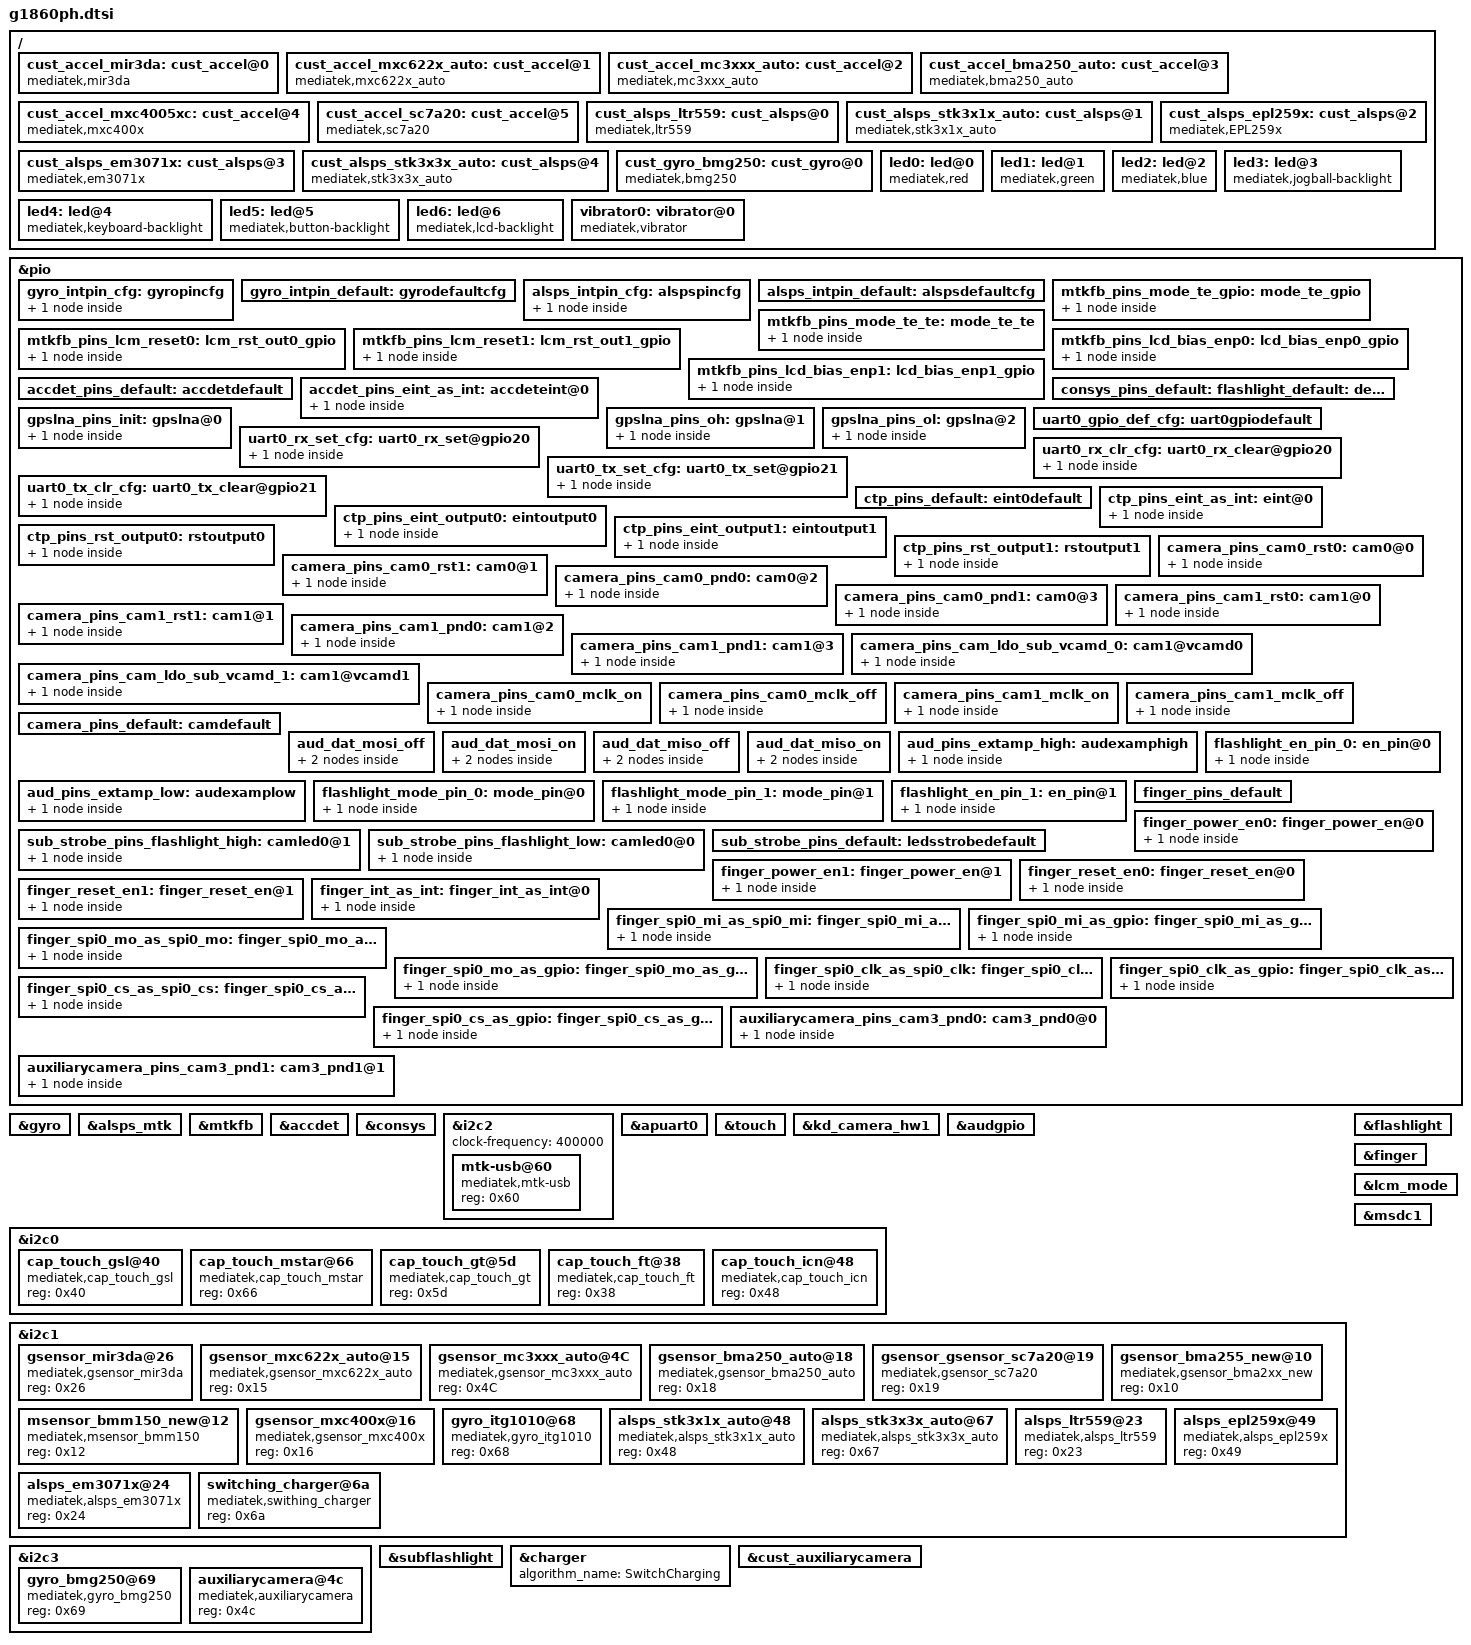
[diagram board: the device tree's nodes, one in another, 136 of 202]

/ {
/*************************
 * sensor  dtsi file
*************************/
	cust_accel_mir3da:cust_accel@0 {
		compatible				= "mediatek,mir3da";
	};
	
	cust_accel_mxc622x_auto:cust_accel@1 {
		compatible				= "mediatek,mxc622x_auto";
	};
	
	cust_accel_mc3xxx_auto:cust_accel@2 {
		compatible				= "mediatek,mc3xxx_auto";
	};
	
	cust_accel_bma250_auto:cust_accel@3 {
		compatible				= "mediatek,bma250_auto";
	};
	cust_accel_mxc4005xc:cust_accel@4 {
		compatible				= "mediatek,mxc400x";
	};
	cust_accel_sc7a20:cust_accel@5 {
		compatible				= "mediatek,sc7a20";
	};
	cust_alsps_ltr559:cust_alsps@0 {
		compatible				= "mediatek,ltr559";
	};
	
	cust_alsps_stk3x1x_auto:cust_alsps@1 {
		compatible				= "mediatek,stk3x1x_auto";
	};
	
	cust_alsps_epl259x:cust_alsps@2 {
		compatible				= "mediatek,EPL259x";
	};
	
	cust_alsps_em3071x:cust_alsps@3 {
		compatible				= "mediatek,em3071x";
	};
	
		cust_alsps_stk3x3x_auto:cust_alsps@4 {
		compatible				= "mediatek,stk3x3x_auto";
	};
	cust_gyro_bmg250:cust_gyro@0 {
		compatible				= "mediatek,bmg250";
	};	
	
	led0:led@0 {
		compatible = "mediatek,red";
		led_mode = <0>;
		data = <&pio 125 0>;
		pwm_config = <0 0 0 0 0>;
	};
	led1:led@1 {
		compatible = "mediatek,green";
		led_mode = <0>;
		data = <2>;
		pwm_config = <0 0 0 0 0>;
	};
	led2:led@2 {
		compatible = "mediatek,blue";
		led_mode = <0>;
		data = <1>;
		pwm_config = <0 0 0 0 0>;
	};
	led3:led@3 {
		compatible = "mediatek,jogball-backlight";
		led_mode = <0>;
		data = <1>;
		pwm_config = <0 0 0 0 0>;
	};
	led4:led@4 {
		compatible = "mediatek,keyboard-backlight";
		led_mode = <0>;
		data = <1>;
		pwm_config = <0 0 0 0 0>;
	};
	led5:led@5 {
		compatible = "mediatek,button-backlight";
		led_mode = <0>;
		data = <1>;
		pwm_config = <0 0 0 0 0>;
	};
	led6:led@6 {
		compatible = "mediatek,lcd-backlight";
		led_mode = <5>;
		data = <1>;
		pwm_config = <0 2 0 0 0>;
	};
	vibrator0:vibrator@0 {
		compatible = "mediatek,vibrator";
		vib_timer = <25>;
		vib_limit = <9>;
		vib_vol= <9>;
	};
};

&cust_gyro_bmg250 {
		i2c_num					= <1>;
		i2c_addr				= <0x68 0 0 0>;
		direction				= <1>;
		power_id				= <0xffff>;
		power_vol				= <0>;
		firlen					= <0>;
		is_batch_supported			= <0>;
};

&cust_accel_mir3da {
		i2c_num				= <1>;
		i2c_addr				= <0x26 0 0 0>;
		direction				= <6>;
		power_id				= <0xffff>;
		power_vol				= <0>;
		firlen					= <0>;
		is_batch_supported			= <0>;
};

&cust_accel_sc7a20 {
		i2c_num					= <1>;
		i2c_addr				= <0x19 0 0 0>;
		direction				= <6>;
		power_id				= <0xffff>;
		power_vol				= <0>;
		firlen					= <0>;
		is_batch_supported			= <0>;
};

&cust_accel_mxc4005xc {
		i2c_num				= <1>;
		i2c_addr				= <0x16 0 0 0>;
		direction				= <0>;
		power_id				= <0xffff>;
		power_vol				= <0>;
		firlen					= <0>;
		is_batch_supported			= <0>;
};	

&cust_accel_mxc622x_auto {
		i2c_num				= <1>;
		i2c_addr				= <0x15 0 0 0>;
		direction				= <3>;
		power_id				= <0xffff>;
		power_vol				= <0>;
		firlen					= <0>;
		is_batch_supported			= <0>;
};
	
&cust_accel_mc3xxx_auto {
		i2c_num				= <1>;
		i2c_addr				= <0x4c 0 0 0>;
		direction				= <3>;
		power_id				= <0xffff>;
		power_vol				= <0>;
		firlen					= <0>;
		is_batch_supported			= <0>;
};
	
&cust_accel_bma250_auto {
		i2c_num				= <1>;
		i2c_addr				= <0x18 0 0 0>;
		direction				= <2>;
		power_id				= <0xffff>;
		power_vol				= <0>;
		firlen					= <0>;
		is_batch_supported			= <0>;
};
	
&cust_alsps_ltr559 {
		i2c_num				= <1>;
		i2c_addr				= <0x23 0 0 0>;
		polling_mode_ps			= <0>;
		polling_mode_als		= <1>;
		power_id				= <0xffff>;
		power_vol				= <0>;
		als_level = <0 328 861 1377 3125 7721 7767 12621 23062 28430 33274 47116 57694 57694 65535>;
		als_value = <0 133 304 502 1004 2005 3058 5005 8008 10010 12000 16000 20000 20000 20000 20000>;
		ps_threshold_high		=  <70>;
		ps_threshold_low		=  <40>;
		is_batch_supported_ps	= <0>;
		is_batch_supported_als	= <0>;
};
		
&cust_alsps_stk3x1x_auto {
		i2c_num				= <1>;
		i2c_addr				= <0x48 0 0 0>;
		polling_mode_ps			= <0>;
		polling_mode_als		= <1>;
		power_id				= <0xffff>;
		power_vol				= <0>;
		als_level	= <5 9 36 59 82 132 205 273 500 845 1136 1545 2364 4655 6982>;
		als_value	= <0 60 80 115 145 180 222 360 460 550 930 1250 1700 2600 5120 7680 10240>;
		ps_threshold_high		=  <90>;
		ps_threshold_low		=  <70>;
		is_batch_supported_ps	= <0>;
		is_batch_supported_als	= <0>;
};

&cust_alsps_stk3x3x_auto {
		i2c_num				= <1>;
		i2c_addr				= <0x67 0 0 0>;
		polling_mode_ps			= <0>;
		polling_mode_als		= <1>;
		power_id				= <0xffff>;
		power_vol				= <0>;
		als_level	= <5   9  36  59  82  132  205  273  500  845  1136  1545  2364  4655  6982>;
		als_value	= <10  10  40  65  90  145  225  300  550  930  1250  1700  2600  5120  7680  10240> ;
		ps_threshold_high		=  <90>;
		ps_threshold_low		=  <70>;
		is_batch_supported_ps	= <0>;
		is_batch_supported_als	= <0>;
};
	
&cust_alsps_epl259x {
		i2c_num				= <1>;
		i2c_addr				= <0x49 0 0 0>;
		polling_mode_ps			= <0>;
		polling_mode_als		= <1>;
		power_id				= <0xffff>;
		power_vol				= <0>;
		als_level = <0 328 861 1377 3125 7721 7767 12621 23062 28430 33274 47116 57694 57694 65535>;
		als_value = <0 133 304 502 1004 2005 3058 5005 8008 10010 12000 16000 20000 20000 20000 20000>;
		ps_threshold_high		=  <70>;
		ps_threshold_low		=  <40>;
		is_batch_supported_ps	= <0>;
		is_batch_supported_als	= <0>;
};

&cust_alsps_em3071x {
		i2c_num				= <1>;
		i2c_addr				= <0x24 0 0 0>;
		polling_mode_ps			= <0>;
		polling_mode_als		= <1>;
		power_id				= <0xffff>;
		power_vol				= <0>;
		als_level = <0 5  9 36 59 82 132 205 273 500 845 1136 1545 2364 4655 6982>;
		als_value = <0 10 60 115 200 260 380 460 580 650 930 1250 1700 2600 5120 7680 10240>;
		ps_threshold_high		=  <90>;
		ps_threshold_low		=  <70>;
		is_batch_supported_ps	= <0>;
		is_batch_supported_als	= <0>;
};

/* sensor gpio standization */
&pio {
	gyro_intpin_cfg: gyropincfg {

	    pins_cmd_dat {
			pins = <PINMUX_GPIO5__FUNC_GPIO5>;
			slew-rate = <0>;
			bias-pull-down = <00>;
		};
	};

	gyro_intpin_default: gyrodefaultcfg {

	};
};

&gyro {
	pinctrl-names = "pin_default", "pin_cfg";
	pinctrl-0 = <&gyro_intpin_default>;
	pinctrl-1 = <&gyro_intpin_cfg>;
	status = "okay";
};

&pio {
	alsps_intpin_cfg: alspspincfg {

		pins_cmd_dat {
			pins = <PINMUX_GPIO1__FUNC_GPIO1>;
			slew-rate = <0>;
			bias-pull-up = <MTK_PUPD_SET_R1R0_01>;
		};
	};

	alsps_intpin_default: alspsdefaultcfg {

	};
};

&alsps_mtk {
	pinctrl-names = "pin_default", "pin_cfg";
	pinctrl-0 = <&alsps_intpin_default>;
	pinctrl-1 = <&alsps_intpin_cfg>;
	status = "okay";
};
/* sensor end */

/* DISPSYS GPIO standardization */
&pio {
	mtkfb_pins_mode_te_gpio: mode_te_gpio {
		pins_cmd_dat {
			pins = <PINMUX_GPIO84__FUNC_DSI_TE>;
		};
	};

	mtkfb_pins_mode_te_te: mode_te_te {
		pins_cmd_dat {
			pins = <PINMUX_GPIO84__FUNC_DSI_TE>;
		};
	};

	mtkfb_pins_lcm_reset0: lcm_rst_out0_gpio {
		pins_cmd_dat {
			pins = <PINMUX_GPIO83__FUNC_LCM_RST>;
			slew-rate = <1>;
			output-low;
		};
	};

	mtkfb_pins_lcm_reset1: lcm_rst_out1_gpio {
		pins_cmd_dat {
			pins = <PINMUX_GPIO83__FUNC_LCM_RST>;
			slew-rate = <1>;
			output-high;
		};
	};

	mtkfb_pins_lcd_bias_enp0: lcd_bias_enp0_gpio {
		pins_cmd_dat {
			pins = <PINMUX_GPIO26__FUNC_GPIO26>;
			slew-rate = <1>;
			output-low;
		};
	};
	mtkfb_pins_lcd_bias_enp1: lcd_bias_enp1_gpio {
		pins_cmd_dat {
			pins = <PINMUX_GPIO26__FUNC_GPIO26>;
			slew-rate = <1>;
			output-high;
		};
	};

};

&mtkfb {
	pinctrl-names = "mode_te_gpio", "mode_te_te", "lcm_rst_out0_gpio",
		"lcm_rst_out1_gpio", "lcd_bias_enp0_gpio", "lcd_bias_enp1_gpio";
	pinctrl-0 = <&mtkfb_pins_mode_te_gpio>;
	pinctrl-1 = <&mtkfb_pins_mode_te_te>;
	pinctrl-2 = <&mtkfb_pins_lcm_reset0>;
	pinctrl-3 = <&mtkfb_pins_lcm_reset1>;
	pinctrl-4 = <&mtkfb_pins_lcd_bias_enp0>;
	pinctrl-5 = <&mtkfb_pins_lcd_bias_enp1>;
	status = "okay";
};
/* DISPSYS GPIO standardization end */


/* accdet start */
&accdet {
	/* accdet micbias voltage: 0x07,2.7v;0x05,2.5v;0x02,1.9v */
	accdet-mic-vol = <7>;
	headset-mode-setting = <0x500 0x500 1 0x1f0 0x800 0x800 0x20 0x44>;
	accdet-plugout-debounce = <256>;
	/*1:ACC mode, 2:low cost without in bias, 6:low cost with in bias*/
	accdet-mic-mode = <1>;
	/* eint_level_trigger: 8,LEVEL_LOW(default);4,LEVEL_HIGH;others,LEVEL_LOW */
	accdet-eint-level-pol = <8>;
	/*0--MD_MAX--UP_MAX--DW_MAX*/
	headset-three-key-threshold = <0 80 220 400>;
	headset-three-key-threshold-CDD = <0 121 192 600>;
	/*0--MD_MAX--VOICE_MAX--UP_MAX--DW_MAX*/
	headset-four-key-threshold = <0 58 121 192 400>;
	/* ACCDET GPIO standardization ACC mode no use */
	pinctrl-names = "default", "state_eint_as_int";
	pinctrl-0 = <&accdet_pins_default>;
	pinctrl-1 = <&accdet_pins_eint_as_int>;
	status = "okay";
};

&pio {
	accdet_pins_default: accdetdefault {
	};
	accdet_pins_eint_as_int: accdeteint@0 {
		pins_cmd_dat {
			pins = <PINMUX_GPIO11__FUNC_GPIO11>;
			slew-rate = <0>;
			bias-disable;
		};
	};
};
/* accdet end */
/* CONSYS GPIO standardization */
&pio {
	consys_pins_default: default {
	};
	gpslna_pins_init: gpslna@0 {
		pins_cmd_dat {
			pins = <PINMUX_GPIO4__FUNC_GPIO4>;
			slew-rate = <0>;
			bias-disable;
			output-low;
		};
	};
	gpslna_pins_oh: gpslna@1 {
		pins_cmd_dat {
			pins = <PINMUX_GPIO4__FUNC_GPIO4>;
			slew-rate = <1>;
			output-high;
		};
	};
	gpslna_pins_ol: gpslna@2 {
		pins_cmd_dat {
			pins = <PINMUX_GPIO4__FUNC_GPIO4>;
			slew-rate = <1>;
			output-low;
		};
	};
};
&consys {
	pinctrl-names = "default", "gps_lna_state_init", "gps_lna_state_oh", "gps_lna_state_ol";
	pinctrl-0 = <&consys_pins_default>;
	pinctrl-1 = <&gpslna_pins_init>;
	pinctrl-2 = <&gpslna_pins_oh>;
	pinctrl-3 = <&gpslna_pins_ol>;
	status = "okay";
};

&i2c2 {
	#address-cells = <1>;
	#size-cells = <0>;
	clock-frequency = <400000>;

	mtk-usb@60 {
		compatible = "mediatek,mtk-usb";
		reg = <0x60>;
		status = "okay";
	};
};
/* IRTX GPIO Start */
/*&irtx_pwm {
	pinctrl-names = "irtx_gpio_led_default", "irtx_gpio_led_set";
	pinctrl-0 = <&irtx_gpio_led_default>;
	pinctrl-1 = <&irtx_gpio_led_set>;
	status = "okay";
};*/
/*&pio {*/
	/* IRTX GPIO Settings -Start */
	/* default: GPIO0, output, high */
/*	irtx_gpio_led_default:irtx_gpio_led_def@gpio12 {
		pins_cmd_dat {
			pins = <PINMUX_GPIO12__FUNC_GPIO12>;
			slew-rate = <1>;
			bias-disable;
			output-low;
			input-schmitt-enable = <0>;
		};
	};

	irtx_gpio_led_set:irtx_gpio_led_set@gpio12 {
		pins_cmd_dat {
			pins = <PINMUX_GPIO12__FUNC_PWM1>;
			slew-rate = <1>;
			output-high;
		};
	};
}; *//* IRTX GPIO Settings -End */

/* UART GPIO */
&apuart0 {
	pinctrl-names = "uart0_gpio_default",
			"uart0_rx_set",
			"uart0_rx_clear",
			"uart0_tx_set",
			"uart0_tx_clear";
	pinctrl-0 = <&uart0_gpio_def_cfg>;
	pinctrl-1 = <&uart0_rx_set_cfg>;
	pinctrl-2 = <&uart0_rx_clr_cfg>;
	pinctrl-3 = <&uart0_tx_set_cfg>;
	pinctrl-4 = <&uart0_tx_clr_cfg>;
	status = "okay";
};

&pio {
	/* UART GPIO Settings - Start */
	/* UART0: rx set, rx clear, tx clear, tx clear*/
	uart0_gpio_def_cfg:uart0gpiodefault {

	};
	uart0_rx_set_cfg:uart0_rx_set@gpio20 {
		pins_cmd_dat {
			pins = <PINMUX_GPIO20__FUNC_UART0RX>;
		};
	};
	uart0_rx_clr_cfg:uart0_rx_clear@gpio20 {
		pins_cmd_dat {
			pins = <PINMUX_GPIO20__FUNC_GPIO20>;
			slew-rate = <1>;
			output-high;
		};
	};
	uart0_tx_set_cfg:uart0_tx_set@gpio21 {
		pins_cmd_dat {
			pins = <PINMUX_GPIO21__FUNC_UART0TX>;
		};
	};
	uart0_tx_clr_cfg:uart0_tx_clear@gpio21 {
		pins_cmd_dat {
			pins = <PINMUX_GPIO21__FUNC_GPIO21>;
			slew-rate = <1>;
			output-high;
		};
	};
};/* UART GPIO end */

/* TOUCH start */
&touch {
	tpd-resolution = <480 854>;
	use-tpd-button = <1>;
	tpd-key-num = <3>;
	tpd-key-local= <139 172 158 0>;
	tpd-key-dim-local = <90 883 100 40 230 883 100 40 370 883 100 40 0 0 0 0>;
	tpd-max-touch-num = <2>;
	tpd-filter-enable = <0>;
	tpd-filter-pixel-density = <106>;
	tpd-filter-custom-prameters = <0 0 0 0 0 0 0 0 0 0 0 0>;
	tpd-filter-custom-speed = <0 0 0>;
	pinctrl-names = "default", "state_eint_as_int", "state_eint_output0", "state_eint_output1",
		"state_rst_output0", "state_rst_output1";
	pinctrl-0 = <&ctp_pins_default>;
	pinctrl-1 = <&ctp_pins_eint_as_int>;
	pinctrl-2 = <&ctp_pins_eint_output0>;
	pinctrl-3 = <&ctp_pins_eint_output1>;
	pinctrl-4 = <&ctp_pins_rst_output0>;
	pinctrl-5 = <&ctp_pins_rst_output1>;
	status = "okay";
};
&pio {
	ctp_pins_default: eint0default {
	};
	ctp_pins_eint_as_int: eint@0 {
		pins_cmd_dat {
			pins = <PINMUX_GPIO6__FUNC_GPIO6>;
			slew-rate = <0>;
			bias-disable;
		};
	};
	ctp_pins_eint_output0: eintoutput0 {
		pins_cmd_dat {
			pins = <PINMUX_GPIO6__FUNC_GPIO6>;
			slew-rate = <1>;
			output-low;
		};
	};
	ctp_pins_eint_output1: eintoutput1 {
		pins_cmd_dat {
			pins = <PINMUX_GPIO6__FUNC_GPIO6>;
			slew-rate = <1>;
			output-high;
		};
	};
	ctp_pins_rst_output0: rstoutput0 {
		pins_cmd_dat {
			pins = <PINMUX_GPIO119__FUNC_GPIO119>;
			slew-rate = <1>;
			output-low;
		};
	};
	ctp_pins_rst_output1: rstoutput1 {
		pins_cmd_dat {
			pins = <PINMUX_GPIO119__FUNC_GPIO119>;
			slew-rate = <1>;
			output-high;
		};
	};
};
/* TOUCH end */

/* CAMERA GPIO standardization */
&pio {
	camera_pins_cam0_rst0: cam0@0 {
		pins_cmd_dat {
			pins = <PINMUX_GPIO29__FUNC_GPIO29>;
			slew-rate = <1>; /*direction 0:in, 1:out*/
			output-low;/*direction out used only. output_low or high*/
		};
	};
	camera_pins_cam0_rst1: cam0@1 {
		pins_cmd_dat {
			pins = <PINMUX_GPIO29__FUNC_GPIO29>;
			slew-rate = <1>;
			output-high;
		};
	};
	camera_pins_cam0_pnd0: cam0@2 {
		pins_cmd_dat {
			pins = <PINMUX_GPIO30__FUNC_GPIO30>;
			slew-rate = <1>;
			output-low;
		};
	};
	camera_pins_cam0_pnd1: cam0@3 {
		pins_cmd_dat {
			pins = <PINMUX_GPIO30__FUNC_GPIO30>;
			slew-rate = <1>;
			output-high;
		};
	};
	camera_pins_cam1_rst0: cam1@0 {
		pins_cmd_dat {
			pins = <PINMUX_GPIO22__FUNC_GPIO22>;
			slew-rate = <1>; /*direction 0:in, 1:out*/
			output-low;/*direction out used only. output_low or high*/
		};
	};
	camera_pins_cam1_rst1: cam1@1 {
		pins_cmd_dat {
			pins = <PINMUX_GPIO22__FUNC_GPIO22>;
			slew-rate = <1>;
			output-high;
		};
	};
	camera_pins_cam1_pnd0: cam1@2 {
		pins_cmd_dat {
			pins = <PINMUX_GPIO23__FUNC_GPIO23>;
			slew-rate = <1>;
			output-low;
		};
	};
	camera_pins_cam1_pnd1: cam1@3 {
		pins_cmd_dat {
			pins = <PINMUX_GPIO23__FUNC_GPIO23>;
			slew-rate = <1>;
			output-high;
		};
	};
	camera_pins_cam_ldo_sub_vcamd_0: cam1@vcamd0 {
		pins_cmd_dat {
			pins = <PINMUX_GPIO9__FUNC_GPIO9>;
			slew-rate = <1>;
			output-low;
		};
	};
	camera_pins_cam_ldo_sub_vcamd_1: cam1@vcamd1 {
		pins_cmd_dat {
			pins = <PINMUX_GPIO9__FUNC_GPIO9>;
			slew-rate = <1>;
			output-high;
		};
	};
	camera_pins_cam0_mclk_on: camera_pins_cam0_mclk_on {
		pins_cmd_dat {
			pins = <PINMUX_GPIO126__FUNC_CMMCLK0>;
		};
	};
	camera_pins_cam0_mclk_off: camera_pins_cam0_mclk_off {
		pins_cmd_dat {
			pins = <PINMUX_GPIO126__FUNC_GPIO126>;
		};
	};
	camera_pins_cam1_mclk_on: camera_pins_cam1_mclk_on {
		pins_cmd_dat {
			pins = <PINMUX_GPIO126__FUNC_CMMCLK0>;
		};
	};
	camera_pins_cam1_mclk_off: camera_pins_cam1_mclk_off {
		pins_cmd_dat {
			pins = <PINMUX_GPIO126__FUNC_GPIO126>;
		};
	};
	camera_pins_default: camdefault {
	};
};

&kd_camera_hw1 {
	pinctrl-names = "default",
			"cam0_rst0", "cam0_rst1", "cam0_pnd0", "cam0_pnd1",
			"cam1_rst0", "cam1_rst1", "cam1_pnd0", "cam1_pnd1",
			"cam_ldo_sub_vcamd_0", "cam_ldo_sub_vcamd_1",
			"cam0_mclk_on", "cam0_mclk_off",
			"cam1_mclk_on", "cam1_mclk_off";

	pinctrl-0 = <&camera_pins_default>;
	pinctrl-1 = <&camera_pins_cam0_rst0>;
	pinctrl-2 = <&camera_pins_cam0_rst1>;
	pinctrl-3 = <&camera_pins_cam0_pnd0>;
	pinctrl-4 = <&camera_pins_cam0_pnd1>;
	pinctrl-5 = <&camera_pins_cam1_rst0>;
	pinctrl-6 = <&camera_pins_cam1_rst1>;
	pinctrl-7 = <&camera_pins_cam1_pnd0>;
	pinctrl-8 = <&camera_pins_cam1_pnd1>;
	pinctrl-9 = <&camera_pins_cam_ldo_sub_vcamd_0>;
	pinctrl-10 = <&camera_pins_cam_ldo_sub_vcamd_1>;
	pinctrl-11 = <&camera_pins_cam0_mclk_on>;
	pinctrl-12 = <&camera_pins_cam0_mclk_off>;
	pinctrl-13 = <&camera_pins_cam1_mclk_on>;
	pinctrl-14 = <&camera_pins_cam1_mclk_off>;
	status = "okay";

};
/* CAMERA GPIO end */

/* AUDIO GPIO standardization */
&audgpio {
	pinctrl-names = "aud_dat_mosi_off",
			"aud_dat_mosi_on",
			"aud_dat_miso_off",
			"aud_dat_miso_on",
			"extamp-pullhigh",
			"extamp-pulllow";
	pinctrl-0 = <&aud_dat_mosi_off>;
	pinctrl-1 = <&aud_dat_mosi_on>;
	pinctrl-2 = <&aud_dat_miso_off>;
	pinctrl-3 = <&aud_dat_miso_on>;
	pinctrl-4 = <&aud_pins_extamp_high>;
	pinctrl-5 = <&aud_pins_extamp_low>;
	status = "okay";
};

&pio {
	aud_dat_mosi_off: aud_dat_mosi_off {
		pins_cmd1_dat {
			pins = <PINMUX_GPIO63__FUNC_GPIO63>;
			input-enable;
			slew-rate = <0>;
			bias-disable;
		};
		pins_cmd2_dat {
			pins = <PINMUX_GPIO64__FUNC_GPIO64>;
			input-enable;
			slew-rate = <0>;
			bias-disable;
		};
	};

	aud_dat_mosi_on: aud_dat_mosi_on {
		pins_cmd1_dat {
			pins = <PINMUX_GPIO63__FUNC_AUD_DAT_MOSI0>;
		};
		pins_cmd2_dat {
			pins = <PINMUX_GPIO64__FUNC_AUD_DAT_MOSI1>;
		};
	};

	aud_dat_miso_off: aud_dat_miso_off {
		pins_cmd1_dat {
			pins = <PINMUX_GPIO67__FUNC_GPIO67>;
			input-enable;
			slew-rate = <0>;
			bias-disable;
		};
		pins_cmd2_dat {
			pins = <PINMUX_GPIO68__FUNC_GPIO68>;
			input-enable;
			slew-rate = <0>;
			bias-disable;
		};
	};

	aud_dat_miso_on: aud_dat_miso_on {
		pins_cmd1_dat {
			pins = <PINMUX_GPIO67__FUNC_AUD_DAT_MISO0>;
		};
		pins_cmd2_dat {
			pins = <PINMUX_GPIO68__FUNC_AUD_DAT_MISO1>;
		};
	};
	aud_pins_extamp_high: audexamphigh {
		pins_cmd_dat {
			pins = <PINMUX_GPIO24__FUNC_GPIO24>;
			slew-rate = <1>;
			output-high;
		};
	};

	aud_pins_extamp_low: audexamplow {
		pins_cmd_dat {
			pins = <PINMUX_GPIO24__FUNC_GPIO24>;
			slew-rate = <1>;
			output-low;
		};
	};

};
/* AUDIO end */

  /*I2C设备兼容如下 注意总线和I2C地址区别*/
&i2c0 {
	cap_touch_gsl@40 {
		compatible = "mediatek,cap_touch_gsl";
		reg = <0x40>;
	};
	
	cap_touch_mstar@66 {
		compatible = "mediatek,cap_touch_mstar";
		reg = <0x66>;
	};
	
	cap_touch_gt@5d {
		compatible = "mediatek,cap_touch_gt";
		reg = <0x5d>;
	};

	cap_touch_ft@38 {
		compatible = "mediatek,cap_touch_ft";
		reg = <0x38>;
	};
	
	cap_touch_icn@48 {
		compatible = "mediatek,cap_touch_icn";
		reg = <0x48>;
	};
};
&i2c1 {
	gsensor_mir3da@26 {
		compatible = "mediatek,gsensor_mir3da";
		reg = <0x26>;
		status = "okay";
	};
	
	gsensor_mxc622x_auto@15 {
		compatible = "mediatek,gsensor_mxc622x_auto";
		reg = <0x15 >;
		status = "okay";
	};
	
	gsensor_mc3xxx_auto@4C {
		compatible = "mediatek,gsensor_mc3xxx_auto";
		reg = <0x4C>;
		status = "okay";
	};
	
	gsensor_bma250_auto@18 {
		compatible = "mediatek,gsensor_bma250_auto";
		reg = <0x18>;
		status = "okay";
	};
	gsensor_gsensor_sc7a20@19 {
		compatible = "mediatek,gsensor_sc7a20";
		reg = <0x19>;
		status = "okay";
	};
	gsensor_bma255_new@10 {
		compatible = "mediatek,gsensor_bma2xx_new";
		reg = <0x10>;
		status = "okay";
	};
	msensor_bmm150_new@12 {
		compatible = "mediatek,msensor_bmm150";
		reg = <0x12>;
		status = "okay";
	};
	
	/*real i2c addr is 0x15, the same as gsensor_mxc622x_auto, so modify the address as 0x16*/	
	gsensor_mxc400x@16{
		compatible = "mediatek,gsensor_mxc400x";
		reg = <0x16>;
		status = "okay";
	};

	gyro_itg1010@68 {
		compatible = "mediatek,gyro_itg1010";
		reg = <0x68>;
		status = "okay";
	};
	

		
	alsps_stk3x1x_auto@48 {
		compatible = "mediatek,alsps_stk3x1x_auto";
		reg = <0x48>;
		status = "okay";
	};
	
	alsps_stk3x3x_auto@67 {
		compatible = "mediatek,alsps_stk3x3x_auto";
		reg = <0x67>;
		status = "okay";
	};
	
	alsps_ltr559@23 {
		compatible = "mediatek,alsps_ltr559";
		reg = <0x23>;
		status = "okay";
	};
	
	alsps_epl259x@49 {
		compatible = "mediatek,alsps_epl259x";
		reg = <0x49>;
		status = "okay";
	};
	
	alsps_em3071x@24 {
		compatible = "mediatek,alsps_em3071x";
		reg = <0x24>;
		status = "okay";
	};

	switching_charger@6a {
		compatible = "mediatek,swithing_charger";
		reg = <0x6a>;
		status = "okay";
	};
};
&i2c2 {
};
&i2c3 {
	gyro_bmg250@69 {
		compatible = "mediatek,gyro_bmg250";
		reg = <0x69>;
		status = "okay";
	};
///Xunhu: using yuv imgsensor for auxiliary camera by trf011{{&&
///Description: 使用yuv摄像头作为辅摄(XUNHU_LPS_AUXILIARYCAMERA_SUPPORT)
	auxiliarycamera@4c {
		compatible = "mediatek,auxiliarycamera";
		reg = <0x4c>;
	};
///&&}}
};

/* flashlight GPIO standardization */
/*h898bc 真假闪兼容*/
#define __XUNHU_GPIO_FLASHLIGHT_MODE__ PINMUX_GPIO3__FUNC_GPIO3
#define __XUNHU_GPIO_FLASHLIGHT_MODE_EN__  PINMUX_GPIO10__FUNC_GPIO10
&pio {
	flashlight_default: default {

	};

	flashlight_mode_pin_0: mode_pin@0 {
		pins_cmd_dat  {
			pins = <__XUNHU_GPIO_FLASHLIGHT_MODE__>;
			slew-rate = <1>;		
			output-low;
		};
	};
	flashlight_mode_pin_1: mode_pin@1 {
		pins_cmd_dat {
			pins = <__XUNHU_GPIO_FLASHLIGHT_MODE__>;
			slew-rate = <1>;
			output-high;
		};
	};
	flashlight_en_pin_0: en_pin@0 {
		pins_cmd_dat {
			pins = <__XUNHU_GPIO_FLASHLIGHT_MODE_EN__>;
			slew-rate = <1>;
			output-low;
		};
	};
	flashlight_en_pin_1: en_pin@1 {
		pins_cmd_dat {
			pins = <__XUNHU_GPIO_FLASHLIGHT_MODE_EN__>;
			slew-rate = <1>;
			output-high;
		};
	};
};

&flashlight {
	pinctrl-names = "default", "mode_pin_0", "mode_pin_1", "en_pin_0", "en_pin_1";
	pinctrl-0 = <&flashlight_default>;
	pinctrl-1 = <&flashlight_mode_pin_0>;
	pinctrl-2 = <&flashlight_mode_pin_1>;
	pinctrl-3 = <&flashlight_en_pin_0>;
	pinctrl-4 = <&flashlight_en_pin_1>;
	status = "okay";
};
/* flashlight end */
/* 不带前摄  屏蔽掉*/
/* SUB_STROBE GPIO standardization */

#define __XUNHU_GPIO_SUB_FLASHLIGHT_EN__    PINMUX_GPIO125__FUNC_GPIO125
&pio {
		sub_strobe_pins_flashlight_high: camled0@1 {
		pins_cmd_dat {
		pins = <__XUNHU_GPIO_SUB_FLASHLIGHT_EN__>;
		slew-rate = <1>;
		output-high;
		};
	};

	sub_strobe_pins_flashlight_low: camled0@0 {
		pins_cmd_dat {
		pins = <__XUNHU_GPIO_SUB_FLASHLIGHT_EN__>;
		slew-rate = <1>; 
		output-low;
		};
	};

	sub_strobe_pins_default: ledsstrobedefault {
	};

};

&subflashlight {
	pinctrl-names = "default",  "subflashlight_high", "subflashlight_low";	  
	
	pinctrl-0 = <&sub_strobe_pins_default>;
	pinctrl-1 = <&sub_strobe_pins_flashlight_high>;
	pinctrl-2 = <&sub_strobe_pins_flashlight_low>;
	status = "okay";

};

/* SUB_STROBE GPIO end */
/*FINGERPRINT GPIO standardization*/
/*指纹SPI调用 严格保持一直*/

#define __XUNHU_GPIO_FINGERPRINT_EINT__    PINMUX_GPIO12__FUNC_GPIO12

#define __XUNHU_GPIO_FINGERPRINT_POWER__ PINMUX_GPIO122__FUNC_GPIO122
#define __XUNHU_GPIO_FINGERPRINT_RST__   PINMUX_GPIO35__FUNC_GPIO35
&finger{
	pinctrl-names = "default",
			"finger_int_as_int",
			"finger_reset_en0",
			"finger_reset_en1",			   
			"finger_power_en0",
			"finger_power_en1",
			/* add for microarray */
			"finger_spi0_mi_as_spi0_mi",
			"finger_spi0_mi_as_gpio",
			"finger_spi0_mo_as_spi0_mo",
			"finger_spi0_mo_as_gpio",
			"finger_spi0_clk_as_spi0_clk",
			"finger_spi0_clk_as_gpio",
			"finger_spi0_cs_as_spi0_cs",
			"finger_spi0_cs_as_gpio";
	pinctrl-0 = <&finger_pins_default>;
	pinctrl-1 = <&finger_int_as_int>;
    pinctrl-2 = <&finger_reset_en0>;
	pinctrl-3 = <&finger_reset_en1>;
	pinctrl-4 = <&finger_power_en0>;
	pinctrl-5 = <&finger_power_en1>; 
	/* add for microarray start */
	pinctrl-6 = <&finger_spi0_mi_as_spi0_mi>;
	pinctrl-7 = <&finger_spi0_mi_as_gpio>;
	pinctrl-8 = <&finger_spi0_mo_as_spi0_mo>;
	pinctrl-9 = <&finger_spi0_mo_as_gpio>;
	pinctrl-10 = <&finger_spi0_clk_as_spi0_clk>;
	pinctrl-11 = <&finger_spi0_clk_as_gpio>;
	pinctrl-12 = <&finger_spi0_cs_as_spi0_cs>;
	pinctrl-13 = <&finger_spi0_cs_as_gpio>;
};


&pio {
/*******************finger pin start ****************/

	finger_pins_default:finger_pins_default{
	};
	
	finger_power_en0:finger_power_en@0{
		    pins_cmd_dat {
			pins = <__XUNHU_GPIO_FINGERPRINT_POWER__>;
			slew-rate = <1>;
			output-low;
		};
	};
	finger_power_en1:finger_power_en@1{
		    pins_cmd_dat {
			pins = <__XUNHU_GPIO_FINGERPRINT_POWER__>;
			slew-rate = <1>;
			output-high;
		};
	};	
	
	finger_reset_en0:finger_reset_en@0{
		    pins_cmd_dat {
			pins = <__XUNHU_GPIO_FINGERPRINT_RST__>;
			slew-rate = <1>;
			output-low;
		};
	};
	
	finger_reset_en1:finger_reset_en@1{
		    pins_cmd_dat {
			pins = <__XUNHU_GPIO_FINGERPRINT_RST__>;
			slew-rate = <1>;
			output-high;
		};
	};

	finger_int_as_int: finger_int_as_int@0{
			pins_cmd_dat {
				pins = <__XUNHU_GPIO_FINGERPRINT_EINT__>;
				slew-rate = <0>;
				bias-pull-up = <00>;
			};
	};
	/* add for microarray start*/
	finger_spi0_mi_as_spi0_mi:finger_spi0_mi_as_spi0_mi@0{
		    pins_cmd_dat {
			pins = <PINMUX_GPIO33__FUNC_SPI0_A_MI>;
			slew-rate = <0>;
			bias-disable;
			output-low;
			input-schmitt-enable = <0>;
		};
	};
	finger_spi0_mi_as_gpio:finger_spi0_mi_as_gpio@0{
		    pins_cmd_dat {
			pins = <PINMUX_GPIO33__FUNC_GPIO33>;
			slew-rate = <0>;
			output-low;
			input-schmitt-enable = <0>;
		};
	};
	finger_spi0_mo_as_spi0_mo:finger_spi0_mo_as_spi0_mo@0{
		    pins_cmd_dat {
			pins = <PINMUX_GPIO34__FUNC_SPI0_A_MO>;
			slew-rate = <1>;
			bias-disable;
			output-low;
			input-schmitt-enable = <0>;
		};
	};
	finger_spi0_mo_as_gpio:finger_spi0_mo_as_gpio@0{
		    pins_cmd_dat {
			pins = <PINMUX_GPIO34__FUNC_GPIO34>;
			slew-rate = <1>;
			output-low;
			input-schmitt-enable = <0>;
		};
	};
	finger_spi0_clk_as_spi0_clk:finger_spi0_clk_as_spi0_clk@0{
		    pins_cmd_dat {
			pins = <PINMUX_GPIO32__FUNC_SPI0_A_CLK>;
			slew-rate = <1>;
			bias-disable;
			output-low;
			input-schmitt-enable = <0>;
		};
	};
	finger_spi0_clk_as_gpio:finger_spi0_clk_as_gpio@0{
		    pins_cmd_dat {
			pins = <PINMUX_GPIO32__FUNC_GPIO32>;
			slew-rate = <1>;
			output-low;
			input-schmitt-enable = <0>;
		};
	};
	finger_spi0_cs_as_spi0_cs:finger_spi0_cs_as_spi0_cs@0{
		    pins_cmd_dat {
			pins = <PINMUX_GPIO31__FUNC_SPI0_A_CSB>;
			slew-rate = <1>;
			bias-disable;
			output-low;
			input-schmitt-enable = <0>;
		};
	};
	finger_spi0_cs_as_gpio:finger_spi0_cs_as_gpio@0{
		    pins_cmd_dat {
			pins = <PINMUX_GPIO31__FUNC_GPIO31>;
			slew-rate = <1>;
			output-low;
			input-schmitt-enable = <0>;
		};
	};
	/* add for microarray end*/
};

/*FINGERPRINT GPIO end*/
/*************************
 * LCM dtsi file
*************************/
/* LCM GPIO Kernal Standardization start */
&lcm_mode {
	lcm_power_gpio = <&pio 26 0>;
	lcm_power2_gpio = <&pio 26 0>;
	status = "okay";
};

&msdc1 {
	cd_level = /bits/ 8 <MSDC_CD_LOW>;
	cd-gpios = <&pio 15 0>;
	status = "okay";
};

&charger {
	algorithm_name = "SwitchCharging";
};

///Xunhu: using yuv imgsensor for auxiliary camera by trf011{{&&
///Description: 使用yuv摄像头作为辅摄(XUNHU_LPS_AUXILIARYCAMERA_SUPPORT)
&pio {
	auxiliarycamera_pins_cam3_pnd0: cam3_pnd0@0 {
	    pins_cmd_dat {
			pins = <PINMUX_GPIO36__FUNC_GPIO36>;/*GPIO_CAMERA_CMPDN1_PIN*/
			slew-rate = <1>;
			output-low;
		};
	};
	auxiliarycamera_pins_cam3_pnd1: cam3_pnd1@1 {
	    pins_cmd_dat {
			pins = <PINMUX_GPIO36__FUNC_GPIO36>;/*GPIO_CAMERA_CMPDN1_PIN*/
			slew-rate = <1>;
			output-high;
		};
	};
	auxiliarycamera_pins_default: default {
	};
};

&cust_auxiliarycamera {
	
	pinctrl-names = "default", "cam3_pnd0", "cam3_pnd1";
	pinctrl-0 = <&auxiliarycamera_pins_default>;
	pinctrl-1 = <&auxiliarycamera_pins_cam3_pnd0>;
	pinctrl-2 = <&auxiliarycamera_pins_cam3_pnd1>;
	/*
	cam3_pnd = <&pio 36 0>;
	status = "okay";
	*/
};
///&&}}
